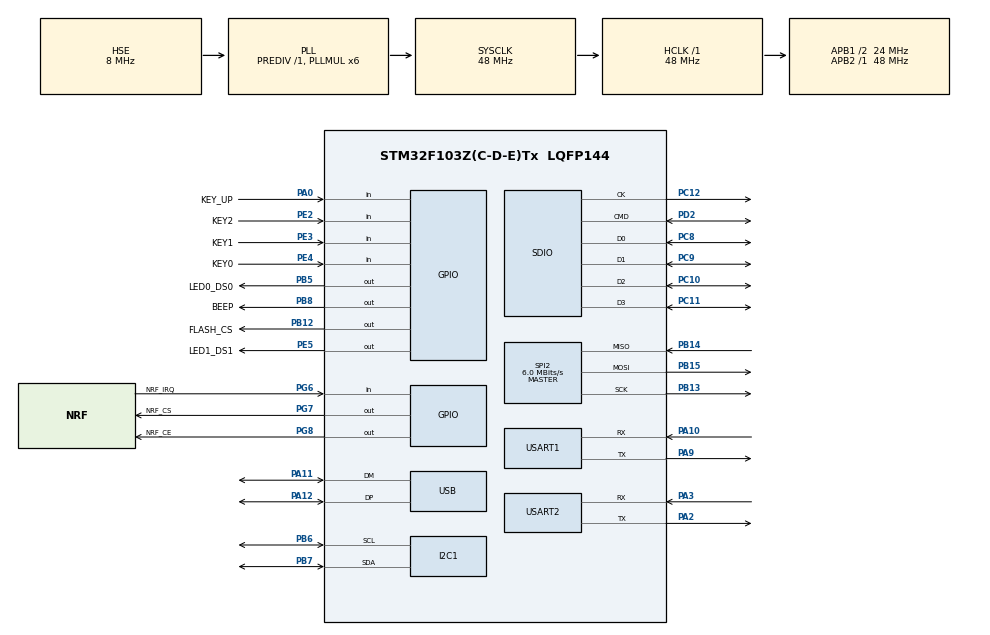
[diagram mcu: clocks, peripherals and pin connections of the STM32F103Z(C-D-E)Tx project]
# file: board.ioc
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Dma.I2C1_RX.1.Direction=DMA_PERIPH_TO_MEMORY
Dma.I2C1_RX.1.Instance=DMA1_Channel7
Dma.I2C1_RX.1.MemDataAlignment=DMA_MDATAALIGN_BYTE
Dma.I2C1_RX.1.MemInc=DMA_MINC_ENABLE
Dma.I2C1_RX.1.Mode=DMA_NORMAL
Dma.I2C1_RX.1.PeriphDataAlignment=DMA_PDATAALIGN_BYTE
Dma.I2C1_RX.1.PeriphInc=DMA_PINC_DISABLE
Dma.I2C1_RX.1.Priority=DMA_PRIORITY_LOW
Dma.I2C1_TX.2.Direction=DMA_MEMORY_TO_PERIPH
Dma.I2C1_TX.2.Instance=DMA1_Channel6
Dma.I2C1_TX.2.MemDataAlignment=DMA_MDATAALIGN_BYTE
Dma.I2C1_TX.2.MemInc=DMA_MINC_ENABLE
Dma.I2C1_TX.2.Mode=DMA_NORMAL
Dma.I2C1_TX.2.PeriphDataAlignment=DMA_PDATAALIGN_BYTE
Dma.I2C1_TX.2.PeriphInc=DMA_PINC_DISABLE
Dma.I2C1_TX.2.Priority=DMA_PRIORITY_LOW
Dma.Request0=SDIO
Dma.Request1=I2C1_RX
Dma.Request2=I2C1_TX
Dma.Request3=SPI2_RX
Dma.Request4=SPI2_TX
Dma.SDIO.0.Direction=DMA_PERIPH_TO_MEMORY
Dma.SDIO.0.Instance=DMA2_Channel4
Dma.SDIO.0.MemDataAlignment=DMA_MDATAALIGN_WORD
Dma.SDIO.0.MemInc=DMA_MINC_ENABLE
Dma.SDIO.0.Mode=DMA_NORMAL
Dma.SDIO.0.PeriphDataAlignment=DMA_PDATAALIGN_WORD
Dma.SDIO.0.PeriphInc=DMA_PINC_DISABLE
Dma.SDIO.0.Priority=DMA_PRIORITY_LOW
Dma.SPI2_RX.3.Direction=DMA_PERIPH_TO_MEMORY
Dma.SPI2_RX.3.Instance=DMA1_Channel4
Dma.SPI2_RX.3.MemDataAlignment=DMA_MDATAALIGN_BYTE
Dma.SPI2_RX.3.MemInc=DMA_MINC_ENABLE
Dma.SPI2_RX.3.Mode=DMA_NORMAL
Dma.SPI2_RX.3.PeriphDataAlignment=DMA_PDATAALIGN_BYTE
Dma.SPI2_RX.3.PeriphInc=DMA_PINC_DISABLE
Dma.SPI2_RX.3.Priority=DMA_PRIORITY_LOW
Dma.SPI2_TX.4.Direction=DMA_MEMORY_TO_PERIPH
Dma.SPI2_TX.4.Instance=DMA1_Channel5
Dma.SPI2_TX.4.MemDataAlignment=DMA_MDATAALIGN_BYTE
Dma.SPI2_TX.4.MemInc=DMA_MINC_ENABLE
Dma.SPI2_TX.4.Mode=DMA_NORMAL
Dma.SPI2_TX.4.PeriphDataAlignment=DMA_PDATAALIGN_BYTE
Dma.SPI2_TX.4.PeriphInc=DMA_PINC_DISABLE
Dma.SPI2_TX.4.Priority=DMA_PRIORITY_LOW
I2C1.DualAddressMode=I2C_DUALADDRESS_DISABLE
I2C1.I2C_Mode=I2C_Standard
IWDG.Prescaler=IWDG_PRESCALER_256
Mcu.Family=STM32F1
Mcu.Name=STM32F103Z(C-D-E)Tx
Mcu.Package=LQFP144
NVIC.DMA1_Channel4_IRQn=true\:14\:0\:true\:false\:true\:false\:true
NVIC.DMA1_Channel5_IRQn=true\:14\:0\:true\:false\:true\:false\:true
NVIC.DMA1_Channel6_IRQn=true\:14\:0\:true\:false\:true\:false\:true
NVIC.DMA1_Channel7_IRQn=true\:14\:0\:true\:false\:true\:false\:true
NVIC.DMA2_Channel4_5_IRQn=true\:15\:0\:true\:false\:true\:false\:true
NVIC.I2C1_ER_IRQn=true\:15\:0\:true\:false\:true\:true\:true
NVIC.I2C1_EV_IRQn=true\:15\:0\:true\:false\:true\:true\:true
NVIC.PriorityGroup=NVIC_PRIORITYGROUP_4
NVIC.SDIO_IRQn=true\:14\:0\:true\:false\:true\:true\:true
NVIC.SPI2_IRQn=true\:15\:0\:true\:false\:true\:true\:true
OSC_IN.Mode=HSE-External-Oscillator
OSC_IN.Signal=RCC_OSC_IN
OSC_OUT.Mode=HSE-External-Oscillator
OSC_OUT.Signal=RCC_OSC_OUT
PA0-WKUP.GPIO_Label=KEY_UP
PA0-WKUP.GPIO_PuPd=GPIO_PULLDOWN
PA0-WKUP.Signal=GPIO_Input
PA10.Mode=Asynchronous
PA10.Signal=USART1_RX
PA11.Mode=Device
PA11.Signal=USB_DM
PA12.Mode=Device
PA12.Signal=USB_DP
PA13.Mode=JTAG_5_pins
PA13.Signal=SYS_JTMS-SWDIO
PA14.Mode=JTAG_5_pins
PA14.Signal=SYS_JTCK-SWCLK
PA15.Mode=JTAG_5_pins
PA15.Signal=SYS_JTDI
PA2.Mode=Asynchronous
PA2.Signal=USART2_TX
PA3.Mode=Asynchronous
PA3.Signal=USART2_RX
PA9.Mode=Asynchronous
PA9.Signal=USART1_TX
PB12.GPIO_Label=FLASH_CS
PB12.PinState=GPIO_PIN_SET
PB12.Signal=GPIO_Output
PB13.Mode=Full_Duplex_Master
PB13.Signal=SPI2_SCK
PB14.Mode=Full_Duplex_Master
PB14.Signal=SPI2_MISO
PB15.Mode=Full_Duplex_Master
PB15.Signal=SPI2_MOSI
PB3.Mode=JTAG_5_pins
PB3.Signal=SYS_JTDO-TRACESWO
PB4.Mode=JTAG_5_pins
PB4.Signal=SYS_NJTRST
PB5.GPIO_Label=LED0_DS0
PB5.Signal=GPIO_Output
PB6.Mode=I2C
PB6.Signal=I2C1_SCL
PB7.Mode=I2C
PB7.Signal=I2C1_SDA
PB8.GPIO_Label=BEEP
PB8.Signal=GPIO_Output
PC10.Mode=SD_4_bits_Wide_bus
PC10.Signal=SDIO_D2
PC11.Mode=SD_4_bits_Wide_bus
PC11.Signal=SDIO_D3
PC12.Mode=SD_4_bits_Wide_bus
PC12.Signal=SDIO_CK
PC14-OSC32_IN.Mode=LSE-External-Oscillator
PC14-OSC32_IN.Signal=RCC_OSC32_IN
PC15-OSC32_OUT.Mode=LSE-External-Oscillator
PC15-OSC32_OUT.Signal=RCC_OSC32_OUT
PC8.Mode=SD_4_bits_Wide_bus
PC8.Signal=SDIO_D0
PC9.Mode=SD_4_bits_Wide_bus
PC9.Signal=SDIO_D1
PD2.Mode=SD_4_bits_Wide_bus
PD2.Signal=SDIO_CMD
PE2.GPIO_Label=KEY2
PE2.GPIO_PuPd=GPIO_PULLUP
PE2.Signal=GPIO_Input
PE3.GPIO_Label=KEY1
PE3.GPIO_PuPd=GPIO_PULLUP
PE3.Signal=GPIO_Input
PE4.GPIO_Label=KEY0
PE4.GPIO_PuPd=GPIO_PULLUP
PE4.Signal=GPIO_Input
PE5.GPIO_Label=LED1_DS1
PE5.Signal=GPIO_Output
PG6.GPIO_Label=NRF_IRQ
PG6.GPIO_PuPd=GPIO_NOPULL
PG6.Signal=GPIO_Input
PG7.GPIO_Label=NRF_CS
PG7.PinState=GPIO_PIN_SET
PG7.Signal=GPIO_Output
PG8.GPIO_Label=NRF_CE
PG8.PinState=GPIO_PIN_SET
PG8.Signal=GPIO_Output
ProjectManager.HeapSize=0x200
ProjectManager.StackSize=0x800
ProjectManager.TargetToolchain=MDK-ARM V5.27
RCC.AHBFreq_Value=48000000
RCC.APB1CLKDivider=RCC_HCLK_DIV2
RCC.APB1Freq_Value=24000000
RCC.APB1TimFreq_Value=48000000
RCC.APB2Freq_Value=48000000
RCC.APB2TimFreq_Value=48000000
RCC.HCLKFreq_Value=48000000
RCC.PLLMUL=RCC_PLL_MUL6
RCC.SYSCLKFreq_VALUE=48000000
RCC.SYSCLKSource=RCC_SYSCLKSOURCE_PLLCLK
RCC.USBFreq_Value=48000000
SPI2.BaudRatePrescaler=SPI_BAUDRATEPRESCALER_4
SPI2.CalculateBaudRate=6.0 MBits/s
SPI2.Direction=SPI_DIRECTION_2LINES
SPI2.Mode=SPI_MODE_MASTER
SPI2.VirtualType=VM_MASTER
USART1.VirtualMode=VM_ASYNC
USART2.VirtualMode=VM_ASYNC
VP_IWDG_VS_IWDG.Mode=IWDG_Activate
VP_RTC_VS_RTC_Activate.Mode=RTC_Enabled
board=custom

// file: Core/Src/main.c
/* USER CODE BEGIN Header */
/**
 ******************************************************************************
 * @file           : main.c
 * @brief          : Main program body
 ******************************************************************************
 * @attention
 *
 * <h2><center>&copy; Copyright (c) 2022 STMicroelectronics.
 * All rights reserved.</center></h2>
 *
 * This software component is licensed by ST under BSD 3-Clause license,
 * the "License"; You may not use this file except in compliance with the
 * License. You may obtain a copy of the License at:
 *                        opensource.org/licenses/BSD-3-Clause
 *
 ******************************************************************************
 */
/* USER CODE END Header */
#include "main.h"

I2C_HandleTypeDef hi2c1;
DMA_HandleTypeDef hdma_i2c1_rx;
DMA_HandleTypeDef hdma_i2c1_tx;

IWDG_HandleTypeDef hiwdg;

RTC_HandleTypeDef hrtc;

SD_HandleTypeDef hsd;
DMA_HandleTypeDef hdma_sdio;

SPI_HandleTypeDef hspi2;
DMA_HandleTypeDef hdma_spi2_rx;
DMA_HandleTypeDef hdma_spi2_tx;

UART_HandleTypeDef huart1;
UART_HandleTypeDef huart2;

PCD_HandleTypeDef hpcd_USB_FS;

void SystemClock_Config(void);
static void MX_GPIO_Init(void);
static void MX_DMA_Init(void);
static void MX_I2C1_Init(void);
static void MX_IWDG_Init(void);
static void MX_SDIO_SD_Init(void);
static void MX_SPI2_Init(void);
static void MX_USART1_UART_Init(void);
static void MX_USART2_UART_Init(void);
static void MX_USB_PCD_Init(void);
static void MX_RTC_Init(void);

/* USER CODE BEGIN 0 */
#if 0
/* USER CODE END 0 */

int main(void)
{
  /* USER CODE BEGIN 1 */
#endif
void mcu_init(void)
{
  /* USER CODE END 1 */

  /* MCU Configuration--------------------------------------------------------*/

  /* Reset of all peripherals, Initializes the Flash interface and the Systick. */
  HAL_Init();

  /* Configure the system clock */
  SystemClock_Config();

  /* Initialize all configured peripherals */
  MX_GPIO_Init();
  MX_DMA_Init();
  MX_I2C1_Init();
  MX_IWDG_Init();
  MX_SDIO_SD_Init();
  MX_SPI2_Init();
  MX_USART1_UART_Init();
  MX_USART2_UART_Init();
  MX_USB_PCD_Init();
  MX_RTC_Init();
  /* USER CODE BEGIN 2 */
	return;
  /* USER CODE END 2 */

  /* Infinite loop */
	while (1)
	{

	}
}

void SystemClock_Config(void)
{
  RCC_OscInitTypeDef RCC_OscInitStruct = {0};
  RCC_ClkInitTypeDef RCC_ClkInitStruct = {0};
  RCC_PeriphCLKInitTypeDef PeriphClkInit = {0};

  /** Initializes the RCC Oscillators according to the specified parameters
  * in the RCC_OscInitTypeDef structure.
  */
  RCC_OscInitStruct.OscillatorType = RCC_OSCILLATORTYPE_LSI|RCC_OSCILLATORTYPE_HSE;
  RCC_OscInitStruct.HSEState = RCC_HSE_ON;
  RCC_OscInitStruct.HSEPredivValue = RCC_HSE_PREDIV_DIV1;
  RCC_OscInitStruct.HSIState = RCC_HSI_ON;
  RCC_OscInitStruct.LSIState = RCC_LSI_ON;
  RCC_OscInitStruct.PLL.PLLState = RCC_PLL_ON;
  RCC_OscInitStruct.PLL.PLLSource = RCC_PLLSOURCE_HSE;
  RCC_OscInitStruct.PLL.PLLMUL = RCC_PLL_MUL6;
  if (HAL_RCC_OscConfig(&RCC_OscInitStruct) != HAL_OK)
  {
    Error_Handler();
  }
  /** Initializes the CPU, AHB and APB buses clocks
  */
  RCC_ClkInitStruct.ClockType = RCC_CLOCKTYPE_HCLK|RCC_CLOCKTYPE_SYSCLK
                              |RCC_CLOCKTYPE_PCLK1|RCC_CLOCKTYPE_PCLK2;
  RCC_ClkInitStruct.SYSCLKSource = RCC_SYSCLKSOURCE_PLLCLK;
  RCC_ClkInitStruct.AHBCLKDivider = RCC_SYSCLK_DIV1;
  RCC_ClkInitStruct.APB1CLKDivider = RCC_HCLK_DIV2;
  RCC_ClkInitStruct.APB2CLKDivider = RCC_HCLK_DIV1;

  if (HAL_RCC_ClockConfig(&RCC_ClkInitStruct, FLASH_LATENCY_1) != HAL_OK)
  {
    Error_Handler();
  }
  PeriphClkInit.PeriphClockSelection = RCC_PERIPHCLK_RTC|RCC_PERIPHCLK_USB;
  PeriphClkInit.RTCClockSelection = RCC_RTCCLKSOURCE_LSI;
  PeriphClkInit.UsbClockSelection = RCC_USBCLKSOURCE_PLL;
  if (HAL_RCCEx_PeriphCLKConfig(&PeriphClkInit) != HAL_OK)
  {
    Error_Handler();
  }
}

static void MX_I2C1_Init(void)
{

  hi2c1.Instance = I2C1;
  hi2c1.Init.ClockSpeed = 100000;
  hi2c1.Init.DutyCycle = I2C_DUTYCYCLE_2;
  hi2c1.Init.OwnAddress1 = 0;
  hi2c1.Init.AddressingMode = I2C_ADDRESSINGMODE_7BIT;
  hi2c1.Init.DualAddressMode = I2C_DUALADDRESS_DISABLE;
  hi2c1.Init.OwnAddress2 = 0;
  hi2c1.Init.GeneralCallMode = I2C_GENERALCALL_DISABLE;
  hi2c1.Init.NoStretchMode = I2C_NOSTRETCH_DISABLE;
  if (HAL_I2C_Init(&hi2c1) != HAL_OK)
  {
    Error_Handler();
  }

}

static void MX_IWDG_Init(void)
{

  hiwdg.Instance = IWDG;
  hiwdg.Init.Prescaler = IWDG_PRESCALER_256;
  hiwdg.Init.Reload = 4095;
  if (HAL_IWDG_Init(&hiwdg) != HAL_OK)
  {
    Error_Handler();
  }

}

static void MX_RTC_Init(void)
{

  /** Initialize RTC Only
  */
  hrtc.Instance = RTC;
  hrtc.Init.AsynchPrediv = RTC_AUTO_1_SECOND;
  hrtc.Init.OutPut = RTC_OUTPUTSOURCE_ALARM;
  if (HAL_RTC_Init(&hrtc) != HAL_OK)
  {
    Error_Handler();
  }

}

static void MX_SDIO_SD_Init(void)
{

  hsd.Instance = SDIO;
  hsd.Init.ClockEdge = SDIO_CLOCK_EDGE_RISING;
  hsd.Init.ClockBypass = SDIO_CLOCK_BYPASS_DISABLE;
  hsd.Init.ClockPowerSave = SDIO_CLOCK_POWER_SAVE_DISABLE;
  hsd.Init.BusWide = SDIO_BUS_WIDE_1B;
  hsd.Init.HardwareFlowControl = SDIO_HARDWARE_FLOW_CONTROL_DISABLE;
  hsd.Init.ClockDiv = 0;
  if (HAL_SD_Init(&hsd) != HAL_OK)
  {
    Error_Handler();
  }
  if (HAL_SD_ConfigWideBusOperation(&hsd, SDIO_BUS_WIDE_4B) != HAL_OK)
  {
    Error_Handler();
  }

}

static void MX_SPI2_Init(void)
{

  /* SPI2 parameter configuration*/
  hspi2.Instance = SPI2;
  hspi2.Init.Mode = SPI_MODE_MASTER;
  hspi2.Init.Direction = SPI_DIRECTION_2LINES;
  hspi2.Init.DataSize = SPI_DATASIZE_8BIT;
  hspi2.Init.CLKPolarity = SPI_POLARITY_LOW;
  hspi2.Init.CLKPhase = SPI_PHASE_1EDGE;
  hspi2.Init.NSS = SPI_NSS_SOFT;
  hspi2.Init.BaudRatePrescaler = SPI_BAUDRATEPRESCALER_4;
  hspi2.Init.FirstBit = SPI_FIRSTBIT_MSB;
  hspi2.Init.TIMode = SPI_TIMODE_DISABLE;
  hspi2.Init.CRCCalculation = SPI_CRCCALCULATION_DISABLE;
  hspi2.Init.CRCPolynomial = 10;
  if (HAL_SPI_Init(&hspi2) != HAL_OK)
  {
    Error_Handler();
  }

}

static void MX_USART1_UART_Init(void)
{

  huart1.Instance = USART1;
  huart1.Init.BaudRate = 115200;
  huart1.Init.WordLength = UART_WORDLENGTH_8B;
  huart1.Init.StopBits = UART_STOPBITS_1;
  huart1.Init.Parity = UART_PARITY_NONE;
  huart1.Init.Mode = UART_MODE_TX_RX;
  huart1.Init.HwFlowCtl = UART_HWCONTROL_NONE;
  huart1.Init.OverSampling = UART_OVERSAMPLING_16;
  if (HAL_UART_Init(&huart1) != HAL_OK)
  {
    Error_Handler();
  }
  /* USER CODE BEGIN USART1_Init 2 */
	__HAL_UART_ENABLE_IT(&huart1, UART_IT_RXNE);//开启串口接受中断
  /* USER CODE END USART1_Init 2 */

}

static void MX_USART2_UART_Init(void)
{

  huart2.Instance = USART2;
  huart2.Init.BaudRate = 115200;
  huart2.Init.WordLength = UART_WORDLENGTH_8B;
  huart2.Init.StopBits = UART_STOPBITS_1;
  huart2.Init.Parity = UART_PARITY_NONE;
  huart2.Init.Mode = UART_MODE_TX_RX;
  huart2.Init.HwFlowCtl = UART_HWCONTROL_NONE;
  huart2.Init.OverSampling = UART_OVERSAMPLING_16;
  if (HAL_UART_Init(&huart2) != HAL_OK)
  {
    Error_Handler();
  }
  /* USER CODE BEGIN USART2_Init 2 */
  __HAL_UART_ENABLE_IT(&huart2, UART_IT_RXNE); //开启串口接受中断/
  /* USER CODE END USART2_Init 2 */

}

static void MX_USB_PCD_Init(void)
{

  hpcd_USB_FS.Instance = USB;
  hpcd_USB_FS.Init.dev_endpoints = 8;
  hpcd_USB_FS.Init.speed = PCD_SPEED_FULL;
  hpcd_USB_FS.Init.low_power_enable = DISABLE;
  hpcd_USB_FS.Init.lpm_enable = DISABLE;
  hpcd_USB_FS.Init.battery_charging_enable = DISABLE;
  if (HAL_PCD_Init(&hpcd_USB_FS) != HAL_OK)
  {
    Error_Handler();
  }

}

static void MX_DMA_Init(void)
{

  /* DMA controller clock enable */
  __HAL_RCC_DMA2_CLK_ENABLE();
  __HAL_RCC_DMA1_CLK_ENABLE();

  /* DMA interrupt init */
  /* DMA1_Channel4_IRQn interrupt configuration */
  HAL_NVIC_SetPriority(DMA1_Channel4_IRQn, 14, 0);
  HAL_NVIC_EnableIRQ(DMA1_Channel4_IRQn);
  /* DMA1_Channel5_IRQn interrupt configuration */
  HAL_NVIC_SetPriority(DMA1_Channel5_IRQn, 14, 0);
  HAL_NVIC_EnableIRQ(DMA1_Channel5_IRQn);
  /* DMA1_Channel6_IRQn interrupt configuration */
  HAL_NVIC_SetPriority(DMA1_Channel6_IRQn, 14, 0);
  HAL_NVIC_EnableIRQ(DMA1_Channel6_IRQn);
  /* DMA1_Channel7_IRQn interrupt configuration */
  HAL_NVIC_SetPriority(DMA1_Channel7_IRQn, 14, 0);
  HAL_NVIC_EnableIRQ(DMA1_Channel7_IRQn);
  /* DMA2_Channel4_5_IRQn interrupt configuration */
  HAL_NVIC_SetPriority(DMA2_Channel4_5_IRQn, 15, 0);
  HAL_NVIC_EnableIRQ(DMA2_Channel4_5_IRQn);

}

static void MX_GPIO_Init(void)
{
  GPIO_InitTypeDef GPIO_InitStruct = {0};

  /* GPIO Ports Clock Enable */
  __HAL_RCC_GPIOE_CLK_ENABLE();
  __HAL_RCC_GPIOC_CLK_ENABLE();
  __HAL_RCC_GPIOA_CLK_ENABLE();
  __HAL_RCC_GPIOB_CLK_ENABLE();
  __HAL_RCC_GPIOG_CLK_ENABLE();
  __HAL_RCC_GPIOD_CLK_ENABLE();

  /*Configure GPIO pin Output Level */
  HAL_GPIO_WritePin(LED1_DS1_GPIO_Port, LED1_DS1_Pin, GPIO_PIN_RESET);

  /*Configure GPIO pin Output Level */
  HAL_GPIO_WritePin(FLASH_CS_GPIO_Port, FLASH_CS_Pin, GPIO_PIN_SET);

  /*Configure GPIO pin Output Level */
  HAL_GPIO_WritePin(GPIOG, NRF_CS_Pin|NRF_CE_Pin, GPIO_PIN_SET);

  /*Configure GPIO pin Output Level */
  HAL_GPIO_WritePin(GPIOB, LED0_DS0_Pin|BEEP_Pin, GPIO_PIN_RESET);

  /*Configure GPIO pins : KEY2_Pin KEY1_Pin KEY0_Pin */
  GPIO_InitStruct.Pin = KEY2_Pin|KEY1_Pin|KEY0_Pin;
  GPIO_InitStruct.Mode = GPIO_MODE_INPUT;
  GPIO_InitStruct.Pull = GPIO_PULLUP;
  HAL_GPIO_Init(GPIOE, &GPIO_InitStruct);

  /*Configure GPIO pin : LED1_DS1_Pin */
  GPIO_InitStruct.Pin = LED1_DS1_Pin;
  GPIO_InitStruct.Mode = GPIO_MODE_OUTPUT_PP;
  GPIO_InitStruct.Pull = GPIO_NOPULL;
  GPIO_InitStruct.Speed = GPIO_SPEED_FREQ_LOW;
  HAL_GPIO_Init(LED1_DS1_GPIO_Port, &GPIO_InitStruct);

  /*Configure GPIO pin : KEY_UP_Pin */
  GPIO_InitStruct.Pin = KEY_UP_Pin;
  GPIO_InitStruct.Mode = GPIO_MODE_INPUT;
  GPIO_InitStruct.Pull = GPIO_PULLDOWN;
  HAL_GPIO_Init(KEY_UP_GPIO_Port, &GPIO_InitStruct);

  /*Configure GPIO pins : FLASH_CS_Pin LED0_DS0_Pin BEEP_Pin */
  GPIO_InitStruct.Pin = FLASH_CS_Pin|LED0_DS0_Pin|BEEP_Pin;
  GPIO_InitStruct.Mode = GPIO_MODE_OUTPUT_PP;
  GPIO_InitStruct.Pull = GPIO_NOPULL;
  GPIO_InitStruct.Speed = GPIO_SPEED_FREQ_LOW;
  HAL_GPIO_Init(GPIOB, &GPIO_InitStruct);

  /*Configure GPIO pin : NRF_IRQ_Pin */
  GPIO_InitStruct.Pin = NRF_IRQ_Pin;
  GPIO_InitStruct.Mode = GPIO_MODE_INPUT;
  GPIO_InitStruct.Pull = GPIO_NOPULL;
  HAL_GPIO_Init(NRF_IRQ_GPIO_Port, &GPIO_InitStruct);

  /*Configure GPIO pins : NRF_CS_Pin NRF_CE_Pin */
  GPIO_InitStruct.Pin = NRF_CS_Pin|NRF_CE_Pin;
  GPIO_InitStruct.Mode = GPIO_MODE_OUTPUT_PP;
  GPIO_InitStruct.Pull = GPIO_NOPULL;
  GPIO_InitStruct.Speed = GPIO_SPEED_FREQ_LOW;
  HAL_GPIO_Init(GPIOG, &GPIO_InitStruct);

}

void Error_Handler(void)
{
}

/************************ (C) COPYRIGHT STMicroelectronics *****END OF FILE****/
